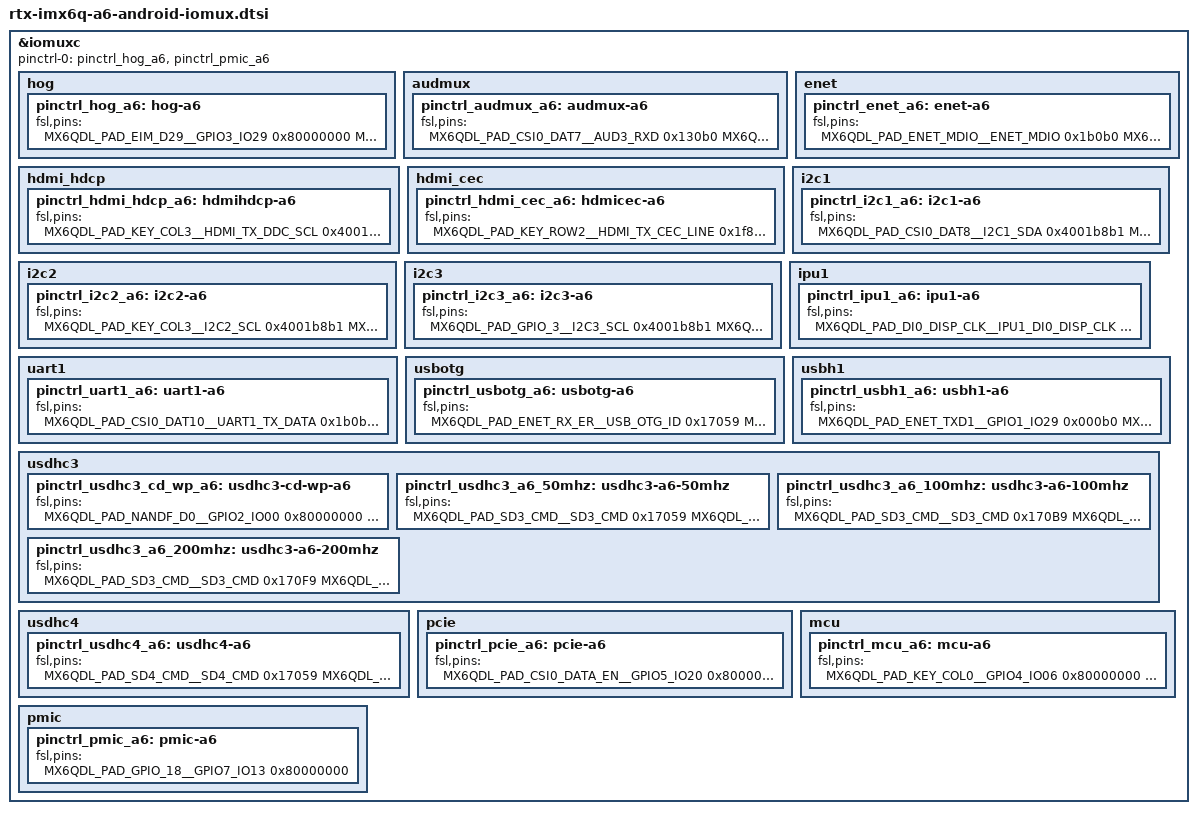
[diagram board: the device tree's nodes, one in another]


&iomuxc {
	pinctrl-names = "default";
	pinctrl-0 = <&pinctrl_hog_a6 &pinctrl_pmic_a6>;

	hog {
		pinctrl_hog_a6: hog-a6 {
			fsl,pins = <
				MX6QDL_PAD_EIM_D29__GPIO3_IO29				0x80000000
				MX6QDL_PAD_GPIO_0__CCM_CLKO1				0x000b0		/* SGTL5000 sys_mclk */
				MX6QDL_PAD_SD3_RST__GPIO7_IO08				0x80000000	/* HEADPHONE_DET */
				MX6QDL_PAD_GPIO_1__WDOG2_B					0x80000000
			>;
		};
	};

	audmux {
		pinctrl_audmux_a6: audmux-a6 {
			fsl,pins = <
				MX6QDL_PAD_CSI0_DAT7__AUD3_RXD				0x130b0
				MX6QDL_PAD_CSI0_DAT4__AUD3_TXC				0x130b0
				MX6QDL_PAD_CSI0_DAT5__AUD3_TXD				0x110b0
				MX6QDL_PAD_CSI0_DAT6__AUD3_TXFS				0x130b0
			>;
		};
	};

	enet {
		pinctrl_enet_a6: enet-a6 {
			fsl,pins = <
				MX6QDL_PAD_ENET_MDIO__ENET_MDIO				0x1b0b0
				MX6QDL_PAD_ENET_MDC__ENET_MDC				0x1b0b0
				MX6QDL_PAD_RGMII_TXC__RGMII_TXC				0x1b0b0
				MX6QDL_PAD_RGMII_TD0__RGMII_TD0				0x1b0b0
				MX6QDL_PAD_RGMII_TD1__RGMII_TD1				0x1b0b0
				MX6QDL_PAD_RGMII_TD2__RGMII_TD2				0x1b0b0
				MX6QDL_PAD_RGMII_TD3__RGMII_TD3				0x1b0b0
				MX6QDL_PAD_RGMII_TX_CTL__RGMII_TX_CTL		0x1b0b0
				MX6QDL_PAD_ENET_REF_CLK__ENET_TX_CLK		0x1b0b0
				MX6QDL_PAD_RGMII_RXC__RGMII_RXC				0x1b0b0
				MX6QDL_PAD_RGMII_RD0__RGMII_RD0				0x1b0b0
				MX6QDL_PAD_RGMII_RD1__RGMII_RD1				0x1b0b0
				MX6QDL_PAD_RGMII_RD2__RGMII_RD2				0x1b0b0
				MX6QDL_PAD_RGMII_RD3__RGMII_RD3				0x1b0b0
				MX6QDL_PAD_RGMII_RX_CTL__RGMII_RX_CTL		0x1b0b0
				MX6QDL_PAD_ENET_RXD1__GPIO1_IO26			0x000b1
				MX6QDL_PAD_ENET_CRS_DV__GPIO1_IO25			0x80000000
			>;
		};
	};

	hdmi_hdcp {
		pinctrl_hdmi_hdcp_a6: hdmihdcp-a6 {
			fsl,pins = <
				MX6QDL_PAD_KEY_COL3__HDMI_TX_DDC_SCL		0x4001b8b1
				MX6QDL_PAD_KEY_ROW3__HDMI_TX_DDC_SDA		0x4001b8b1
			>;
		};
	};

	hdmi_cec {
		pinctrl_hdmi_cec_a6: hdmicec-a6 {
			fsl,pins = <
				MX6QDL_PAD_KEY_ROW2__HDMI_TX_CEC_LINE		0x1f8b0
			>;
		};
	};

	i2c1 {
		pinctrl_i2c1_a6: i2c1-a6 {
			fsl,pins = <
				MX6QDL_PAD_CSI0_DAT8__I2C1_SDA				0x4001b8b1
				MX6QDL_PAD_CSI0_DAT9__I2C1_SCL				0x4001b8b1
			>;
		};
	};

	i2c2 {
		pinctrl_i2c2_a6: i2c2-a6 {
			fsl,pins = <
				MX6QDL_PAD_KEY_COL3__I2C2_SCL				0x4001b8b1
				MX6QDL_PAD_KEY_ROW3__I2C2_SDA				0x4001b8b1
			>;
		};
	};

	i2c3 {
		pinctrl_i2c3_a6: i2c3-a6 {
			fsl,pins = <
				MX6QDL_PAD_GPIO_3__I2C3_SCL					0x4001b8b1
				MX6QDL_PAD_GPIO_6__I2C3_SDA					0x4001b8b1
			>;
		};
	};

	ipu1 {
		pinctrl_ipu1_a6: ipu1-a6 {
			fsl,pins = <
				MX6QDL_PAD_DI0_DISP_CLK__IPU1_DI0_DISP_CLK	0x10
				MX6QDL_PAD_DI0_PIN15__IPU1_DI0_PIN15		0x10
				MX6QDL_PAD_DI0_PIN2__IPU1_DI0_PIN02			0x10
				MX6QDL_PAD_DI0_PIN3__IPU1_DI0_PIN03			0x10
				MX6QDL_PAD_DI0_PIN4__IPU1_DI0_PIN04			0x80000000
				MX6QDL_PAD_DISP0_DAT0__IPU1_DISP0_DATA00	0x10
				MX6QDL_PAD_DISP0_DAT1__IPU1_DISP0_DATA01	0x10
				MX6QDL_PAD_DISP0_DAT2__IPU1_DISP0_DATA02	0x10
				MX6QDL_PAD_DISP0_DAT3__IPU1_DISP0_DATA03	0x10
				MX6QDL_PAD_DISP0_DAT4__IPU1_DISP0_DATA04	0x10
				MX6QDL_PAD_DISP0_DAT5__IPU1_DISP0_DATA05	0x10
				MX6QDL_PAD_DISP0_DAT6__IPU1_DISP0_DATA06	0x10
				MX6QDL_PAD_DISP0_DAT7__IPU1_DISP0_DATA07	0x10
				MX6QDL_PAD_DISP0_DAT8__IPU1_DISP0_DATA08	0x10
				MX6QDL_PAD_DISP0_DAT9__IPU1_DISP0_DATA09	0x10
				MX6QDL_PAD_DISP0_DAT10__IPU1_DISP0_DATA10	0x10
				MX6QDL_PAD_DISP0_DAT11__IPU1_DISP0_DATA11	0x10
				MX6QDL_PAD_DISP0_DAT12__IPU1_DISP0_DATA12	0x10
				MX6QDL_PAD_DISP0_DAT13__IPU1_DISP0_DATA13	0x10
				MX6QDL_PAD_DISP0_DAT14__IPU1_DISP0_DATA14	0x10
				MX6QDL_PAD_DISP0_DAT15__IPU1_DISP0_DATA15	0x10
				MX6QDL_PAD_DISP0_DAT16__IPU1_DISP0_DATA16	0x10
				MX6QDL_PAD_DISP0_DAT17__IPU1_DISP0_DATA17	0x10
				MX6QDL_PAD_DISP0_DAT18__IPU1_DISP0_DATA18	0x10
				MX6QDL_PAD_DISP0_DAT19__IPU1_DISP0_DATA19	0x10
				MX6QDL_PAD_DISP0_DAT20__IPU1_DISP0_DATA20	0x10
				MX6QDL_PAD_DISP0_DAT21__IPU1_DISP0_DATA21	0x10
				MX6QDL_PAD_DISP0_DAT22__IPU1_DISP0_DATA22	0x10
				MX6QDL_PAD_DISP0_DAT23__IPU1_DISP0_DATA23	0x10
				MX6QDL_PAD_GPIO_4__GPIO1_IO04				0x80000000	/* VGA DAC ENABLE */
				MX6QDL_PAD_GPIO_19__GPIO4_IO05				0x80000000	/* VGA I2C ENABLE */
			>;
		};

	};

	uart1 {
		pinctrl_uart1_a6: uart1-a6 {
			fsl,pins = <
				MX6QDL_PAD_CSI0_DAT10__UART1_TX_DATA		0x1b0b1
				MX6QDL_PAD_CSI0_DAT11__UART1_RX_DATA		0x1b0b1
				MX6QDL_PAD_EIM_D19__UART1_CTS_B				0x1b0b1
				MX6QDL_PAD_EIM_D20__UART1_RTS_B				0x1b0b1
			>;
		};
	};

	usbotg {
		pinctrl_usbotg_a6: usbotg-a6 {
			fsl,pins = <
				MX6QDL_PAD_ENET_RX_ER__USB_OTG_ID			0x17059
				MX6QDL_PAD_EIM_D22__GPIO3_IO22				0x000b0
				MX6QDL_PAD_EIM_D21__USB_OTG_OC				0x1b0b0
			>;
		};
	};

	usbh1 {
		pinctrl_usbh1_a6: usbh1-a6 {
			fsl,pins = <
				MX6QDL_PAD_ENET_TXD1__GPIO1_IO29			0x000b0
				MX6QDL_PAD_EIM_D30__USB_H1_OC				0x1b0b0
				MX6QDL_PAD_GPIO_17__GPIO7_IO12				0x80000000
			>;
		};
	};

	usdhc3 {
		pinctrl_usdhc3_cd_wp_a6: usdhc3-cd-wp-a6 {
			fsl,pins = <
				MX6QDL_PAD_NANDF_D0__GPIO2_IO00				0x80000000	/* SD3_CD */
				MX6QDL_PAD_NANDF_D1__GPIO2_IO01				0x80000000	/* SD3_WP */
			>;
		};
		
		pinctrl_usdhc3_a6_50mhz: usdhc3-a6-50mhz {						/* 50Mhz */
			fsl,pins = <
				MX6QDL_PAD_SD3_CMD__SD3_CMD					0x17059
				MX6QDL_PAD_SD3_CLK__SD3_CLK					0x10059
				MX6QDL_PAD_SD3_DAT0__SD3_DATA0				0x17059
				MX6QDL_PAD_SD3_DAT1__SD3_DATA1				0x17059
				MX6QDL_PAD_SD3_DAT2__SD3_DATA2				0x17059
				MX6QDL_PAD_SD3_DAT3__SD3_DATA3				0x17059
			>;
		};

		pinctrl_usdhc3_a6_100mhz: usdhc3-a6-100mhz { 					/* 100Mhz */
			fsl,pins = <
				MX6QDL_PAD_SD3_CMD__SD3_CMD					0x170B9
				MX6QDL_PAD_SD3_CLK__SD3_CLK					0x100B9
				MX6QDL_PAD_SD3_DAT0__SD3_DATA0				0x170B9
				MX6QDL_PAD_SD3_DAT1__SD3_DATA1				0x170B9
				MX6QDL_PAD_SD3_DAT2__SD3_DATA2				0x170B9
				MX6QDL_PAD_SD3_DAT3__SD3_DATA3				0x170B9
			>;
		};

		pinctrl_usdhc3_a6_200mhz: usdhc3-a6-200mhz { 					/* 200Mhz */
			fsl,pins = <
				MX6QDL_PAD_SD3_CMD__SD3_CMD					0x170F9
				MX6QDL_PAD_SD3_CLK__SD3_CLK					0x100F9
				MX6QDL_PAD_SD3_DAT0__SD3_DATA0				0x170F9
				MX6QDL_PAD_SD3_DAT1__SD3_DATA1				0x170F9
				MX6QDL_PAD_SD3_DAT2__SD3_DATA2				0x170F9
				MX6QDL_PAD_SD3_DAT3__SD3_DATA3				0x170F9
			>;
		};
	};

	usdhc4 {
		pinctrl_usdhc4_a6: usdhc4-a6 {
			fsl,pins = <
				MX6QDL_PAD_SD4_CMD__SD4_CMD					0x17059
				MX6QDL_PAD_SD4_CLK__SD4_CLK					0x10059
				MX6QDL_PAD_SD4_DAT0__SD4_DATA0				0x17059
				MX6QDL_PAD_SD4_DAT1__SD4_DATA1				0x17059
				MX6QDL_PAD_SD4_DAT2__SD4_DATA2				0x17059
				MX6QDL_PAD_SD4_DAT3__SD4_DATA3				0x17059
				MX6QDL_PAD_SD4_DAT4__SD4_DATA4				0x17059
				MX6QDL_PAD_SD4_DAT5__SD4_DATA5				0x17059
				MX6QDL_PAD_SD4_DAT6__SD4_DATA6				0x17059
				MX6QDL_PAD_SD4_DAT7__SD4_DATA7				0x17059
			>;
		};
	};

	pcie {
		pinctrl_pcie_a6: pcie-a6 {
			fsl,pins = <
				MX6QDL_PAD_CSI0_DATA_EN__GPIO5_IO20			0x80000000	/* PCIE_WAKE_B */
				MX6QDL_PAD_GPIO_16__GPIO7_IO11				0x80000000	/* PCIE_RST */
				MX6QDL_PAD_EIM_D18__GPIO3_IO18				0x80000000	/* PCIE_PWR_EN */
				MX6QDL_PAD_KEY_COL4__GPIO4_IO14				0x80000000	/* PCIE_DIS_B */
			>;
		};
	};

	mcu {
		pinctrl_mcu_a6: mcu-a6 {
			fsl,pins = <
				MX6QDL_PAD_KEY_COL0__GPIO4_IO06				0x80000000	/* MCU Reset */
				MX6QDL_PAD_KEY_ROW0__GPIO4_IO07				0x80000000	/* MCU_UPDATE_PWR_ON */
				MX6QDL_PAD_KEY_COL2__GPIO4_IO10				0x80000000	/* MCU_BOOT_EN */
			>;
		};
	};

	pmic {
		pinctrl_pmic_a6: pmic-a6 {
			fsl,pins = <
				MX6QDL_PAD_GPIO_18__GPIO7_IO13				0x80000000	/* PMIC INT */
			>;
		};
	};
};

